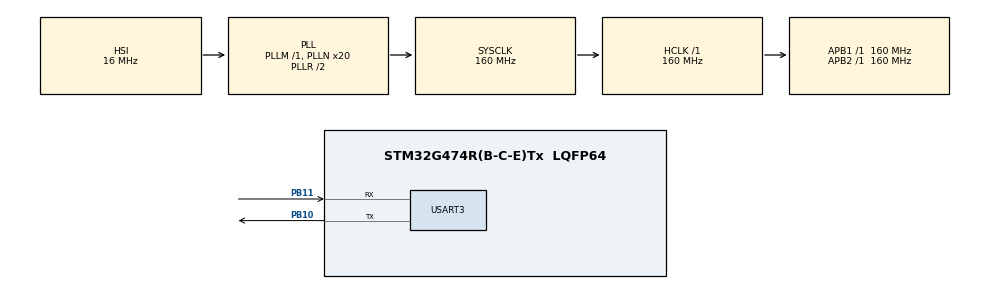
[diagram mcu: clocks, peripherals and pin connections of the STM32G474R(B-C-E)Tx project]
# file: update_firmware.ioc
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Mcu.Family=STM32G4
Mcu.Name=STM32G474R(B-C-E)Tx
Mcu.Package=LQFP64
NVIC.PriorityGroup=NVIC_PRIORITYGROUP_4
NVIC.TIM2_IRQn=true\:0\:0\:false\:false\:true\:true\:true\:true
NVIC.USART3_IRQn=true\:0\:0\:false\:false\:true\:true\:true\:true
PA13.Mode=Serial_Wire
PA13.Signal=SYS_JTMS-SWDIO
PA14.Mode=Serial_Wire
PA14.Signal=SYS_JTCK-SWCLK
PB10.Mode=Asynchronous
PB10.Signal=USART3_TX
PB11.Mode=Asynchronous
PB11.Signal=USART3_RX
ProjectManager.HeapSize=0x200
ProjectManager.StackSize=0x400
ProjectManager.TargetToolchain=MDK-ARM V5.32
RCC.ADC12Freq_Value=160000000
RCC.ADC345Freq_Value=160000000
RCC.AHBFreq_Value=160000000
RCC.APB1Freq_Value=160000000
RCC.APB1TimFreq_Value=160000000
RCC.APB2Freq_Value=160000000
RCC.APB2TimFreq_Value=160000000
RCC.CortexFreq_Value=160000000
RCC.EXTERNAL_CLOCK_VALUE=12288000
RCC.HCLKFreq_Value=160000000
RCC.HSE_VALUE=8000000
RCC.HSI48_VALUE=48000000
RCC.HSI_VALUE=16000000
RCC.LSE_VALUE=32768
RCC.PLLN=20
RCC.SYSCLKFreq_VALUE=160000000
RCC.SYSCLKSource=RCC_SYSCLKSOURCE_PLLCLK
RCC.USBFreq_Value=160000000
RCC.VCOOutputFreq_Value=320000000
TIM2.PeriodNoDither=9999
TIM2.Prescaler=20000-1
USART3.VirtualMode-Asynchronous=VM_ASYNC
VP_SYS_VS_DBSignals.Mode=DisableDeadBatterySignals
VP_TIM2_VS_ClockSourceINT.Mode=Internal
board=custom

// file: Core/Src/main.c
/* USER CODE BEGIN Header */
/**
  ******************************************************************************
  * @file           : main.c
  * @brief          : Main program body
  ******************************************************************************
  * @attention
  *
  * Copyright (c) 2025 STMicroelectronics.
  * All rights reserved.
  *
  * This software is licensed under terms that can be found in the LICENSE file
  * in the root directory of this software component.
  * If no LICENSE file comes with this software, it is provided AS-IS.
  *
  ******************************************************************************
  */
/* USER CODE END Header */
#include "main.h"

/* USER CODE BEGIN Includes */
#include "string.h"
#include "FlashG4.h"
#include "ProcessData.h"
/* USER CODE END Includes */

TIM_HandleTypeDef htim2;

UART_HandleTypeDef huart3;

/* USER CODE BEGIN PV */
char RxDataUSART3[1024];
char RxDataChar[1];
volatile uint16_t RxDataIndex = 0;

char RxCmdString[5] = {0};
volatile uint16_t RxCmdIndex = 0;

/* Flag check if uart3 received completed respond or not */
int isReceivedRespond = 0;
int bIsUpdating = 0;

volatile uint8_t enable_reset = 1;
/* USER CODE END PV */

void SystemClock_Config(void);
static void MX_GPIO_Init(void);
static void MX_TIM2_Init(void);
static void MX_USART3_UART_Init(void);
/* USER CODE BEGIN PFP */
void printDebug(char *debugText)
{
	HAL_UART_Transmit(&huart3,(uint8_t *)debugText,(uint16_t)strlen(debugText),100);
}

void respondDevice(char *respond)
{
	HAL_UART_Transmit(&huart3,(uint8_t *)respond,(uint16_t)strlen(respond),100);
}

void ResetMainProgVar()
{
	ClearBufferAndResetWriteVariable();
	RxDataIndex = 0;
	bIsUpdating = 0;
}

void HAL_UART_RxCpltCallback(UART_HandleTypeDef *huart)
{
	if(huart->Instance == USART3)
  {
		if (enable_reset == 1) {
			RxCmdString[RxCmdIndex++] = RxDataChar[0];
			HAL_UART_Receive_IT(&huart3, (uint8_t*)RxDataChar, 1);
			if (RxCmdIndex == 5) {
				// First 5 bytes are EB-4; Charger have to reboot
				if (strcmp(RxCmdString, "EB-4;") == 0) {
					HAL_NVIC_SystemReset();
				} else {
					RxDataUSART3[0] = RxCmdString[0];
					RxDataUSART3[1] = RxCmdString[1];
					RxDataUSART3[2] = RxCmdString[2];
					RxDataUSART3[3] = RxCmdString[3];
					RxDataUSART3[4] = RxCmdString[4];
					bIsUpdating = 1;
					RxDataIndex = 5;
					enable_reset = 0;
				}
			}
		} else {
			enable_reset = 0;
			bIsUpdating = 1;
			uint8_t RxLength = 0;
			RxDataUSART3[RxDataIndex++] = RxDataChar[0];
			uint8_t processResult = error;
			HAL_UART_Receive_IT(&huart3, (uint8_t*)RxDataChar, 1);

			if(RxDataChar[0] == '\n') // current receive each line
			{
				isReceivedRespond = 1;
				processResult = ProcessData(RxDataUSART3);
				if(processResult == error)
				{
					ResetMainProgVar();
					bIsUpdating = 0;
					respondDevice("ER");
//					printDebug("Error\r\n");
//					printDebug("Ready to Update !!!!\r\n");
					enable_reset = 1;
					memset(RxCmdString, 0, sizeof(RxCmdString));
					RxCmdIndex = 0;
				}
				else if(processResult == completed)
				{
					respondDevice("ED");
//					printDebug("Completed\r\n");
					Set_Update_Firm_Completed(0x37);
					bIsUpdating = 0;
					HAL_NVIC_SystemReset();
				}
				else
				{
					// transmit respond to device
					respondDevice("OK");
				}
				TIM2->CNT = 0;
				RxDataIndex = 0;
			}
		}
	}
}

void HAL_TIM_PeriodElapsedCallback(TIM_HandleTypeDef *htim) {
    if (htim->Instance == TIM2)
		{
			if(bIsUpdating == 1)
			{
				ResetMainProgVar();
				respondDevice("TO");
//				printDebug("Time out\r\n");
				bIsUpdating = 0;
				enable_reset = 1;
				memset(RxCmdString, 0, sizeof(RxCmdString));
				RxCmdIndex = 0;
			}
    }
}
/* USER CODE END PFP */

int main(void)
{

  /* USER CODE BEGIN 1 */
	SCB->VTOR = (uint32_t)0x08020000;
	__enable_irq();
  /* USER CODE END 1 */

  /* MCU Configuration--------------------------------------------------------*/

  /* Reset of all peripherals, Initializes the Flash interface and the Systick. */
  HAL_Init();

  /* Configure the system clock */
  SystemClock_Config();

  /* Initialize all configured peripherals */
  MX_GPIO_Init();
  MX_TIM2_Init();
  MX_USART3_UART_Init();
  /* USER CODE BEGIN 2 */
//	uint64_t data2[] = {0x2,0x1,0x3,0x4,0x5,0x6,0x7,0x8,0x9};
//	uint64_t Rx_Data[30];
//	Flash_Write_Data(0x08020000 , (uint64_t *)data2, 9);
//  Flash_Read_Data(0x08020000 , Rx_Data, 10);
	HAL_TIM_Base_Start_IT(&htim2);
	HAL_UART_Receive_IT(&huart3, (uint8_t*)RxDataChar, 1);
	printDebug("Update firmware mode !!!!!!\r\n");
//	Set_Update_Firm_Completed(0x37);
	uint64_t tmpKey[1];
	Flash_Read_Data(0x0803F800, tmpKey, 1);
	if(tmpKey[0] == 0x35)
	{
		printDebug("Memory read: 35\r\n");
	}
	else if(tmpKey[0] == 0x37)
	{
		printDebug("Memory read: 37\r\n");
	}
	else
	{
		printDebug("Unindentified Mem\r\n");
	}
	printDebug("Ready to Update !!!!\r\n");
  /* USER CODE END 2 */

  /* Infinite loop */
  while (1)
  {

  }
}

void SystemClock_Config(void)
{
  RCC_OscInitTypeDef RCC_OscInitStruct = {0};
  RCC_ClkInitTypeDef RCC_ClkInitStruct = {0};

  /** Configure the main internal regulator output voltage
  */
  HAL_PWREx_ControlVoltageScaling(PWR_REGULATOR_VOLTAGE_SCALE1_BOOST);

  /** Initializes the RCC Oscillators according to the specified parameters
  * in the RCC_OscInitTypeDef structure.
  */
  RCC_OscInitStruct.OscillatorType = RCC_OSCILLATORTYPE_HSI;
  RCC_OscInitStruct.HSIState = RCC_HSI_ON;
  RCC_OscInitStruct.HSICalibrationValue = RCC_HSICALIBRATION_DEFAULT;
  RCC_OscInitStruct.PLL.PLLState = RCC_PLL_ON;
  RCC_OscInitStruct.PLL.PLLSource = RCC_PLLSOURCE_HSI;
  RCC_OscInitStruct.PLL.PLLM = RCC_PLLM_DIV1;
  RCC_OscInitStruct.PLL.PLLN = 20;
  RCC_OscInitStruct.PLL.PLLP = RCC_PLLP_DIV2;
  RCC_OscInitStruct.PLL.PLLQ = RCC_PLLQ_DIV2;
  RCC_OscInitStruct.PLL.PLLR = RCC_PLLR_DIV2;
  if (HAL_RCC_OscConfig(&RCC_OscInitStruct) != HAL_OK)
  {
    Error_Handler();
  }

  /** Initializes the CPU, AHB and APB buses clocks
  */
  RCC_ClkInitStruct.ClockType = RCC_CLOCKTYPE_HCLK|RCC_CLOCKTYPE_SYSCLK
                              |RCC_CLOCKTYPE_PCLK1|RCC_CLOCKTYPE_PCLK2;
  RCC_ClkInitStruct.SYSCLKSource = RCC_SYSCLKSOURCE_PLLCLK;
  RCC_ClkInitStruct.AHBCLKDivider = RCC_SYSCLK_DIV1;
  RCC_ClkInitStruct.APB1CLKDivider = RCC_HCLK_DIV1;
  RCC_ClkInitStruct.APB2CLKDivider = RCC_HCLK_DIV1;

  if (HAL_RCC_ClockConfig(&RCC_ClkInitStruct, FLASH_LATENCY_4) != HAL_OK)
  {
    Error_Handler();
  }
}

static void MX_TIM2_Init(void)
{

  TIM_ClockConfigTypeDef sClockSourceConfig = {0};
  TIM_MasterConfigTypeDef sMasterConfig = {0};

  htim2.Instance = TIM2;
  htim2.Init.Prescaler = 20000-1;
  htim2.Init.CounterMode = TIM_COUNTERMODE_UP;
  htim2.Init.Period = 9999;
  htim2.Init.ClockDivision = TIM_CLOCKDIVISION_DIV1;
  htim2.Init.AutoReloadPreload = TIM_AUTORELOAD_PRELOAD_DISABLE;
  if (HAL_TIM_Base_Init(&htim2) != HAL_OK)
  {
    Error_Handler();
  }
  sClockSourceConfig.ClockSource = TIM_CLOCKSOURCE_INTERNAL;
  if (HAL_TIM_ConfigClockSource(&htim2, &sClockSourceConfig) != HAL_OK)
  {
    Error_Handler();
  }
  sMasterConfig.MasterOutputTrigger = TIM_TRGO_RESET;
  sMasterConfig.MasterSlaveMode = TIM_MASTERSLAVEMODE_DISABLE;
  if (HAL_TIMEx_MasterConfigSynchronization(&htim2, &sMasterConfig) != HAL_OK)
  {
    Error_Handler();
  }

}

static void MX_USART3_UART_Init(void)
{

  huart3.Instance = USART3;
  huart3.Init.BaudRate = 115200;
  huart3.Init.WordLength = UART_WORDLENGTH_8B;
  huart3.Init.StopBits = UART_STOPBITS_1;
  huart3.Init.Parity = UART_PARITY_NONE;
  huart3.Init.Mode = UART_MODE_TX_RX;
  huart3.Init.HwFlowCtl = UART_HWCONTROL_NONE;
  huart3.Init.OverSampling = UART_OVERSAMPLING_16;
  huart3.Init.OneBitSampling = UART_ONE_BIT_SAMPLE_DISABLE;
  huart3.Init.ClockPrescaler = UART_PRESCALER_DIV1;
  huart3.AdvancedInit.AdvFeatureInit = UART_ADVFEATURE_NO_INIT;
  if (HAL_UART_Init(&huart3) != HAL_OK)
  {
    Error_Handler();
  }
  if (HAL_UARTEx_SetTxFifoThreshold(&huart3, UART_TXFIFO_THRESHOLD_1_8) != HAL_OK)
  {
    Error_Handler();
  }
  if (HAL_UARTEx_SetRxFifoThreshold(&huart3, UART_RXFIFO_THRESHOLD_1_8) != HAL_OK)
  {
    Error_Handler();
  }
  if (HAL_UARTEx_DisableFifoMode(&huart3) != HAL_OK)
  {
    Error_Handler();
  }

}

static void MX_GPIO_Init(void)
{

  /* GPIO Ports Clock Enable */
  __HAL_RCC_GPIOB_CLK_ENABLE();
  __HAL_RCC_GPIOA_CLK_ENABLE();

}

void Error_Handler(void)
{
  __disable_irq();
  while (1)
  {
  }
}
